VERSION ""

NS_ :

BS_:

BU_: Vector__XXX

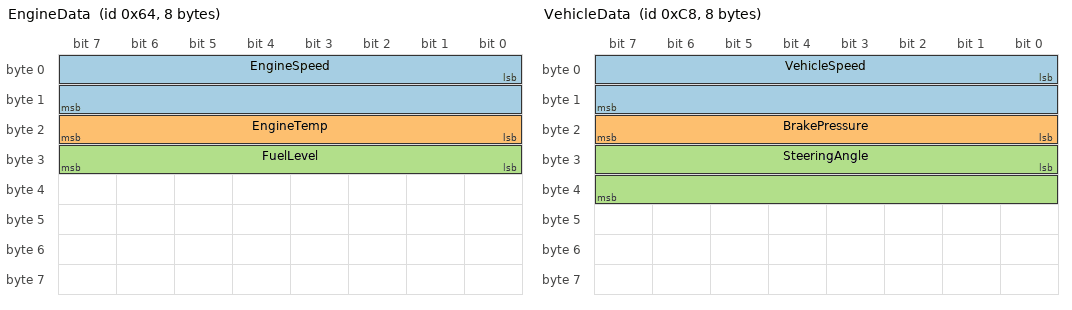
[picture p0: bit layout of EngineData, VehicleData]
BO_ 100 EngineData: 8 Vector__XXX
 SG_ EngineSpeed : 0|16@1+ (0.125,0) [0|8031.875] "rpm" Vector__XXX
 SG_ EngineTemp : 16|8@1+ (1,-40) [-40|215] "degC" Vector__XXX
 SG_ FuelLevel : 24|8@1+ (0.392157,0) [0|100] "%" Vector__XXX

BO_ 200 VehicleData: 8 Vector__XXX
 SG_ VehicleSpeed : 0|16@1+ (0.00390625,0) [0|255.99609375] "km/h" Vector__XXX
 SG_ BrakePressure : 16|8@1+ (0.1,0) [0|25.5] "bar" Vector__XXX
 SG_ SteeringAngle : 24|16@1- (0.1,-3276.8) [-3276.8|3276.7] "deg" Vector__XXX
